# f28004x_asys_regs register map
Vendor: Texas Instruments
Peripheral module from a debugger description file (folder C2000).
Address unit: 16 bits
Registers are 16-bit, read-write, no defined reset value unless marked. A register's access mark holds for its fields unless they carry their own. Offsets are as the file gives them; lines under a group give offsets from that group; [hi:lo] are bit positions; {n}, {i} and the like mark numbered series; 'fields as' and 'values as' point back to an identical list; <NAME> marks a mode.

## ASYS_REGS — ASYS Registers
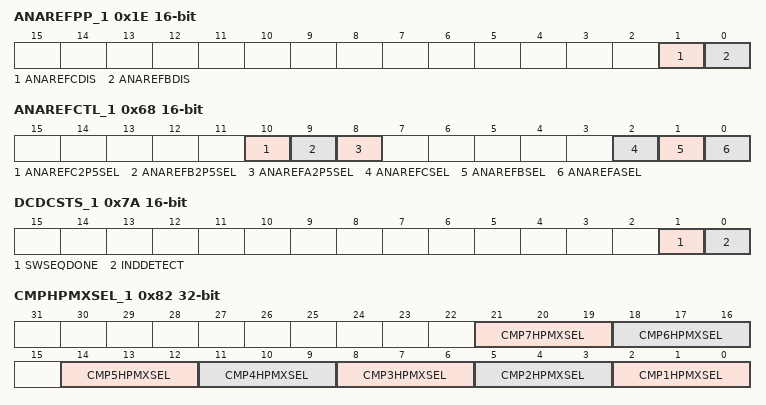
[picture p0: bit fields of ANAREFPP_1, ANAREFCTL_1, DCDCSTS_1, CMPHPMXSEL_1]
0x1E ANAREFPP_1 access not given — ADC Analog Reference Peripheral Properties register
  [1] ANAREFCDIS — Disable ANAREFC (access R/WOnce)
  [0] ANAREFBDIS — Disable ANAREFB (access R/WOnce)
0x60 TSNSCTL_1 — Temperature Sensor Control Register
  [0] ENABLE — Temperature Sensor Enable
0x68 ANAREFCTL_1 — Analog Reference Control Register
  [10] ANAREFC2P5SEL — Analog Reference B Select
  [9] ANAREFB2P5SEL — Analog Reference B Select
  [8] ANAREFA2P5SEL — Analog Reference A Select
  [2] ANAREFCSEL — Analog Reference C Select
  [1] ANAREFBSEL — Analog Reference B Select
  [0] ANAREFASEL — Analog Reference A Select
0x78 DCDCCTL_1 32-bit — DC-DC control register.
  [0] DCDCEN — DCDC Enable
0x7A DCDCSTS_1 access not given — DC-DC status register.
  [1] SWSEQDONE ro — Switch sequence to DC-DC done.
  [0] INDDETECT — Inductor Detected (access R/W=1)
0x82 CMPHPMXSEL_1 32-bit — Bits to select one of the many sources on CopmHP inputs. Refer to Pimux diagram for details.
  [21:19] CMP7HPMXSEL — CMP7HPMXSEL bits
  [18:16] CMP6HPMXSEL — CMP6HPMXSEL bits
  [3n-1:3n-3] CMP{n}HPMXSEL (n=1..5) — CMP{n}HPMXSEL bits
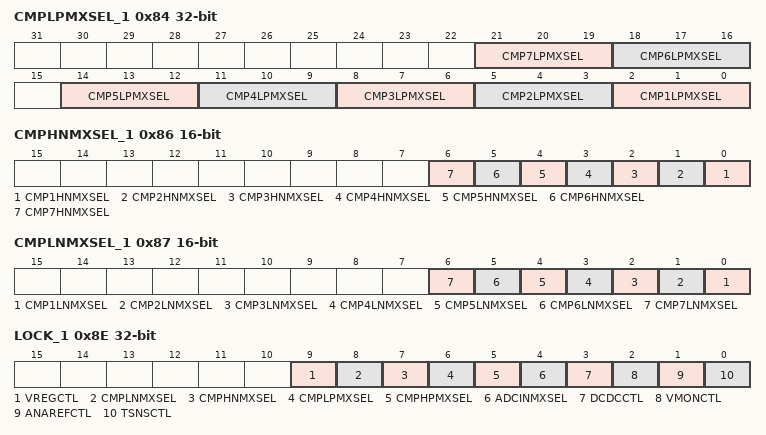
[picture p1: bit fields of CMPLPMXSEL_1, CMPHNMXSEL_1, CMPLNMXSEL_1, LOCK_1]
0x84 CMPLPMXSEL_1 32-bit — Bits to select one of the many sources on CopmLP inputs. Refer to Pimux diagram for details.
  [21:19] CMP7LPMXSEL — CMP7LPMXSEL bits
  [18:16] CMP6LPMXSEL — CMP6LPMXSEL bits
  [3n-1:3n-3] CMP{n}LPMXSEL (n=1..5) — CMP{n}LPMXSEL bits
0x86 CMPHNMXSEL_1 — Bits to select one of the many sources on CopmHN inputs. Refer to Pimux diagram for details.
  [n-1] CMP{n}HNMXSEL (n=1..7) — CMP{n}HNMXSEL bits
0x87 CMPLNMXSEL_1 — Bits to select one of the many sources on CopmLN inputs. Refer to Pimux diagram for details.
  [n-1] CMP{n}LNMXSEL (n=1..7) — CMP{n}LNMXSEL bits
0x8E LOCK_1 32-bit access not given — Lock Register
  [9] VREGCTL — VREGCTL Register lock bit (access R/SOnce)
  [8] CMPLNMXSEL — CMPLNMXSEL Register lock bit (access R/SOnce)
  [7] CMPHNMXSEL — CMPHNMXSEL Register lock bit (access R/SOnce)
  [6] CMPLPMXSEL — CMPLPMXSEL Register lock bit (access R/SOnce)
  [5] CMPHPMXSEL — CMPHPMXSEL Register lock bit (access R/SOnce)
  [4] ADCINMXSEL — ADCINMXSEL Register lock bit (access R/SOnce)
  [3] DCDCCTL — DCDCCTL Register lock bit (access R/SOnce)
  [2] VMONCTL — VMONCTL Register lock bit (access R/SOnce)
  [1] ANAREFCTL — ANAREFCTL Register lock bit (access R/SOnce)
  [0] TSNSCTL — TSNSCTL Register lock bit (access R/SOnce)
